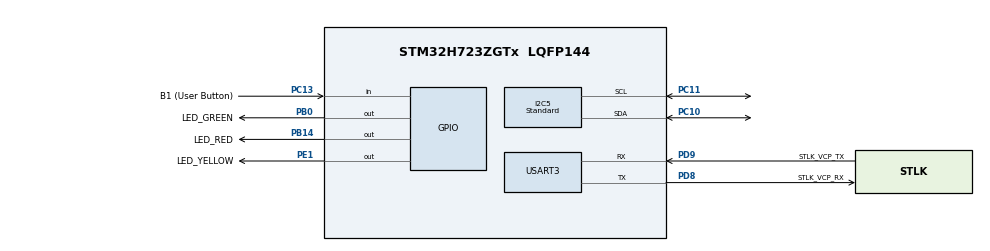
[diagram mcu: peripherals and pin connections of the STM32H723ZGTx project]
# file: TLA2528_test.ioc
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CORTEX_M7.default_mode_Activation=1
I2C5.I2C_Speed_Mode=I2C_Standard
I2C5.Timing=0x20A0A3F6
Mcu.Family=STM32H7
Mcu.Name=STM32H723ZGTx
Mcu.Package=LQFP144
NVIC.PriorityGroup=NVIC_PRIORITYGROUP_4
PA13(JTMS/SWDIO).GPIO_Label=SWDIO
PA13(JTMS/SWDIO).Signal=DEBUG_JTMS-SWDIO
PA14(JTCK/SWCLK).GPIO_Label=SWCLK
PA14(JTCK/SWCLK).Signal=DEBUG_JTCK-SWCLK
PB0.GPIO_Label=LED_GREEN
PB0.Signal=GPIO_Output
PB14.GPIO_Label=LED_RED
PB14.Signal=GPIO_Output
PC10.Mode=I2C
PC10.Signal=I2C5_SDA
PC11.Mode=I2C
PC11.Signal=I2C5_SCL
PC13.GPIO_Label=B1 (User Button)
PC13.Signal=GPIO_Input
PC14-OSC32_IN.Signal=RCC_OSC32_IN
PC15-OSC32_OUT.Signal=RCC_OSC32_OUT
PD8.GPIO_Label=STLK_VCP_RX
PD8.Mode=Asynchronous
PD8.Signal=USART3_TX
PD9.GPIO_Label=STLK_VCP_TX
PD9.Mode=Asynchronous
PD9.Signal=USART3_RX
PE1.GPIO_Label=LED_YELLOW
PE1.Signal=GPIO_Output
ProjectManager.HeapSize=0x200
ProjectManager.StackSize=0x400
ProjectManager.TargetToolchain=STM32CubeIDE
RCC.ADCFreq_Value=608000000
RCC.APB1Freq_Value=125000000
RCC.APB2Freq_Value=125000000
RCC.APB3Freq_Value=125000000
RCC.APB4Freq_Value=125000000
RCC.CortexFreq_Value=500000000
RCC.D1PPRE=RCC_APB3_DIV2
RCC.D2PPRE1=RCC_APB1_DIV2
RCC.D2PPRE2=RCC_APB2_DIV2
RCC.D3PPRE=RCC_APB4_DIV2
RCC.DIVM1=4
RCC.DIVM2=1
RCC.DIVN1=31
RCC.DIVN2=19
RCC.DIVP1=1
RCC.DIVQ1=4
RCC.HCLKFreq_Value=250000000
RCC.HPRE=RCC_HCLK_DIV2
RCC.HSE_VALUE=8000000
RCC.PLLFRACN=2048
RCC.SYSCLKFreq_VALUE=500000000
RCC.SYSCLKSource=RCC_SYSCLKSOURCE_PLLCLK
RCC.USBCLockSelection=RCC_USBCLKSOURCE_HSI48
RCC.USBFreq_Value=48000000
USART3.VirtualMode-Asynchronous=VM_ASYNC
VP_MEMORYMAP_VS_MEMORYMAP.Mode=CurAppReg
board=NUCLEO-H723ZG

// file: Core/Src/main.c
/* USER CODE BEGIN Header */
/**
  ******************************************************************************
  * @file           : main.c
  * @brief          : Main program body
  ******************************************************************************
  * @attention
  *
  * Copyright (c) 2025 STMicroelectronics.
  * All rights reserved.
  *
  * This software is licensed under terms that can be found in the LICENSE file
  * in the root directory of this software component.
  * If no LICENSE file comes with this software, it is provided AS-IS.
  *
  ******************************************************************************
  */
/* USER CODE END Header */
#include "main.h"

/* USER CODE BEGIN Includes */
#include "stdio.h"
/* USER CODE END Includes */

/* USER CODE BEGIN PTD */
#include "tla2528.h"
/* USER CODE END PTD */

I2C_HandleTypeDef hi2c5;

UART_HandleTypeDef huart3;

/* USER CODE BEGIN PV */
int _write(int file, char *ptr, int len) {
	HAL_UART_Transmit(&huart3, (uint8_t*) ptr, len, HAL_MAX_DELAY);
	return len;
}
/* USER CODE END PV */

void SystemClock_Config(void);
static void MPU_Config(void);
static void MX_GPIO_Init(void);
static void MX_I2C5_Init(void);
static void MX_USART3_UART_Init(void);

int main(void)
{

  /* MPU Configuration--------------------------------------------------------*/
  MPU_Config();

  /* MCU Configuration--------------------------------------------------------*/

  /* Reset of all peripherals, Initializes the Flash interface and the Systick. */
  HAL_Init();

  /* Configure the system clock */
  SystemClock_Config();

  /* Initialize all configured peripherals */
  MX_GPIO_Init();
  MX_I2C5_Init();
  MX_USART3_UART_Init();
  /* USER CODE BEGIN 2 */
  TLA2528_Init();
  /* USER CODE END 2 */

  /* Infinite loop */
  while (1)
  {
      TLA2528_ReadChannels(); // อ่านค่าทุกช่อง
       printf("Ch1: %d, Ch2: %d, Ch3: %d, Ch4: %d, Ch5: %d, Ch6: %d, Ch7: %d, Ch8: %d \n",
             TLA2528_GetChannel(0),
              TLA2528_GetChannel(1),
             TLA2528_GetChannel(2),
              TLA2528_GetChannel(3),
              TLA2528_GetChannel(4),
              TLA2528_GetChannel(5),
              TLA2528_GetChannel(6),
              TLA2528_GetChannel(7));
       HAL_Delay(1000);
  }
}

void SystemClock_Config(void)
{
  RCC_OscInitTypeDef RCC_OscInitStruct = {0};
  RCC_ClkInitTypeDef RCC_ClkInitStruct = {0};

  /** Supply configuration update enable
  */
  HAL_PWREx_ConfigSupply(PWR_LDO_SUPPLY);

  /** Configure the main internal regulator output voltage
  */
  __HAL_PWR_VOLTAGESCALING_CONFIG(PWR_REGULATOR_VOLTAGE_SCALE0);

  while(!__HAL_PWR_GET_FLAG(PWR_FLAG_VOSRDY)) {}

  /** Initializes the RCC Oscillators according to the specified parameters
  * in the RCC_OscInitTypeDef structure.
  */
  RCC_OscInitStruct.OscillatorType = RCC_OSCILLATORTYPE_HSI;
  RCC_OscInitStruct.HSIState = RCC_HSI_DIV1;
  RCC_OscInitStruct.HSICalibrationValue = 64;
  RCC_OscInitStruct.PLL.PLLState = RCC_PLL_ON;
  RCC_OscInitStruct.PLL.PLLSource = RCC_PLLSOURCE_HSI;
  RCC_OscInitStruct.PLL.PLLM = 4;
  RCC_OscInitStruct.PLL.PLLN = 31;
  RCC_OscInitStruct.PLL.PLLP = 1;
  RCC_OscInitStruct.PLL.PLLQ = 4;
  RCC_OscInitStruct.PLL.PLLR = 2;
  RCC_OscInitStruct.PLL.PLLRGE = RCC_PLL1VCIRANGE_3;
  RCC_OscInitStruct.PLL.PLLVCOSEL = RCC_PLL1VCOWIDE;
  RCC_OscInitStruct.PLL.PLLFRACN = 2048;
  if (HAL_RCC_OscConfig(&RCC_OscInitStruct) != HAL_OK)
  {
    Error_Handler();
  }

  /** Initializes the CPU, AHB and APB buses clocks
  */
  RCC_ClkInitStruct.ClockType = RCC_CLOCKTYPE_HCLK|RCC_CLOCKTYPE_SYSCLK
                              |RCC_CLOCKTYPE_PCLK1|RCC_CLOCKTYPE_PCLK2
                              |RCC_CLOCKTYPE_D3PCLK1|RCC_CLOCKTYPE_D1PCLK1;
  RCC_ClkInitStruct.SYSCLKSource = RCC_SYSCLKSOURCE_PLLCLK;
  RCC_ClkInitStruct.SYSCLKDivider = RCC_SYSCLK_DIV1;
  RCC_ClkInitStruct.AHBCLKDivider = RCC_HCLK_DIV2;
  RCC_ClkInitStruct.APB3CLKDivider = RCC_APB3_DIV2;
  RCC_ClkInitStruct.APB1CLKDivider = RCC_APB1_DIV2;
  RCC_ClkInitStruct.APB2CLKDivider = RCC_APB2_DIV2;
  RCC_ClkInitStruct.APB4CLKDivider = RCC_APB4_DIV2;

  if (HAL_RCC_ClockConfig(&RCC_ClkInitStruct, FLASH_LATENCY_3) != HAL_OK)
  {
    Error_Handler();
  }
}

static void MX_I2C5_Init(void)
{

  hi2c5.Instance = I2C5;
  hi2c5.Init.Timing = 0x20A0A3F6;
  hi2c5.Init.OwnAddress1 = 0;
  hi2c5.Init.AddressingMode = I2C_ADDRESSINGMODE_7BIT;
  hi2c5.Init.DualAddressMode = I2C_DUALADDRESS_DISABLE;
  hi2c5.Init.OwnAddress2 = 0;
  hi2c5.Init.OwnAddress2Masks = I2C_OA2_NOMASK;
  hi2c5.Init.GeneralCallMode = I2C_GENERALCALL_DISABLE;
  hi2c5.Init.NoStretchMode = I2C_NOSTRETCH_DISABLE;
  if (HAL_I2C_Init(&hi2c5) != HAL_OK)
  {
    Error_Handler();
  }

  /** Configure Analogue filter
  */
  if (HAL_I2CEx_ConfigAnalogFilter(&hi2c5, I2C_ANALOGFILTER_ENABLE) != HAL_OK)
  {
    Error_Handler();
  }

  /** Configure Digital filter
  */
  if (HAL_I2CEx_ConfigDigitalFilter(&hi2c5, 0) != HAL_OK)
  {
    Error_Handler();
  }

}

static void MX_USART3_UART_Init(void)
{

  huart3.Instance = USART3;
  huart3.Init.BaudRate = 115200;
  huart3.Init.WordLength = UART_WORDLENGTH_8B;
  huart3.Init.StopBits = UART_STOPBITS_1;
  huart3.Init.Parity = UART_PARITY_NONE;
  huart3.Init.Mode = UART_MODE_TX_RX;
  huart3.Init.HwFlowCtl = UART_HWCONTROL_NONE;
  huart3.Init.OverSampling = UART_OVERSAMPLING_16;
  huart3.Init.OneBitSampling = UART_ONE_BIT_SAMPLE_DISABLE;
  huart3.Init.ClockPrescaler = UART_PRESCALER_DIV1;
  huart3.AdvancedInit.AdvFeatureInit = UART_ADVFEATURE_NO_INIT;
  if (HAL_UART_Init(&huart3) != HAL_OK)
  {
    Error_Handler();
  }
  if (HAL_UARTEx_SetTxFifoThreshold(&huart3, UART_TXFIFO_THRESHOLD_1_8) != HAL_OK)
  {
    Error_Handler();
  }
  if (HAL_UARTEx_SetRxFifoThreshold(&huart3, UART_RXFIFO_THRESHOLD_1_8) != HAL_OK)
  {
    Error_Handler();
  }
  if (HAL_UARTEx_DisableFifoMode(&huart3) != HAL_OK)
  {
    Error_Handler();
  }

}

static void MX_GPIO_Init(void)
{
  GPIO_InitTypeDef GPIO_InitStruct = {0};

  /* GPIO Ports Clock Enable */
  __HAL_RCC_GPIOC_CLK_ENABLE();
  __HAL_RCC_GPIOB_CLK_ENABLE();
  __HAL_RCC_GPIOD_CLK_ENABLE();
  __HAL_RCC_GPIOA_CLK_ENABLE();
  __HAL_RCC_GPIOE_CLK_ENABLE();

  /*Configure GPIO pin Output Level */
  HAL_GPIO_WritePin(GPIOB, LED_GREEN_Pin|LED_RED_Pin, GPIO_PIN_RESET);

  /*Configure GPIO pin Output Level */
  HAL_GPIO_WritePin(LED_YELLOW_GPIO_Port, LED_YELLOW_Pin, GPIO_PIN_RESET);

  /*Configure GPIO pin : B1_Pin */
  GPIO_InitStruct.Pin = B1_Pin;
  GPIO_InitStruct.Mode = GPIO_MODE_INPUT;
  GPIO_InitStruct.Pull = GPIO_NOPULL;
  HAL_GPIO_Init(B1_GPIO_Port, &GPIO_InitStruct);

  /*Configure GPIO pins : LED_GREEN_Pin LED_RED_Pin */
  GPIO_InitStruct.Pin = LED_GREEN_Pin|LED_RED_Pin;
  GPIO_InitStruct.Mode = GPIO_MODE_OUTPUT_PP;
  GPIO_InitStruct.Pull = GPIO_NOPULL;
  GPIO_InitStruct.Speed = GPIO_SPEED_FREQ_LOW;
  HAL_GPIO_Init(GPIOB, &GPIO_InitStruct);

  /*Configure GPIO pin : LED_YELLOW_Pin */
  GPIO_InitStruct.Pin = LED_YELLOW_Pin;
  GPIO_InitStruct.Mode = GPIO_MODE_OUTPUT_PP;
  GPIO_InitStruct.Pull = GPIO_NOPULL;
  GPIO_InitStruct.Speed = GPIO_SPEED_FREQ_LOW;
  HAL_GPIO_Init(LED_YELLOW_GPIO_Port, &GPIO_InitStruct);

}

 /* MPU Configuration */

void MPU_Config(void)
{
  MPU_Region_InitTypeDef MPU_InitStruct = {0};

  /* Disables the MPU */
  HAL_MPU_Disable();

  /** Initializes and configures the Region and the memory to be protected
  */
  MPU_InitStruct.Enable = MPU_REGION_ENABLE;
  MPU_InitStruct.Number = MPU_REGION_NUMBER0;
  MPU_InitStruct.BaseAddress = 0x0;
  MPU_InitStruct.Size = MPU_REGION_SIZE_4GB;
  MPU_InitStruct.SubRegionDisable = 0x87;
  MPU_InitStruct.TypeExtField = MPU_TEX_LEVEL0;
  MPU_InitStruct.AccessPermission = MPU_REGION_NO_ACCESS;
  MPU_InitStruct.DisableExec = MPU_INSTRUCTION_ACCESS_DISABLE;
  MPU_InitStruct.IsShareable = MPU_ACCESS_SHAREABLE;
  MPU_InitStruct.IsCacheable = MPU_ACCESS_NOT_CACHEABLE;
  MPU_InitStruct.IsBufferable = MPU_ACCESS_NOT_BUFFERABLE;

  HAL_MPU_ConfigRegion(&MPU_InitStruct);
  /* Enables the MPU */
  HAL_MPU_Enable(MPU_PRIVILEGED_DEFAULT);

}

void Error_Handler(void)
{
  __disable_irq();
  while (1)
  {
  }
}
